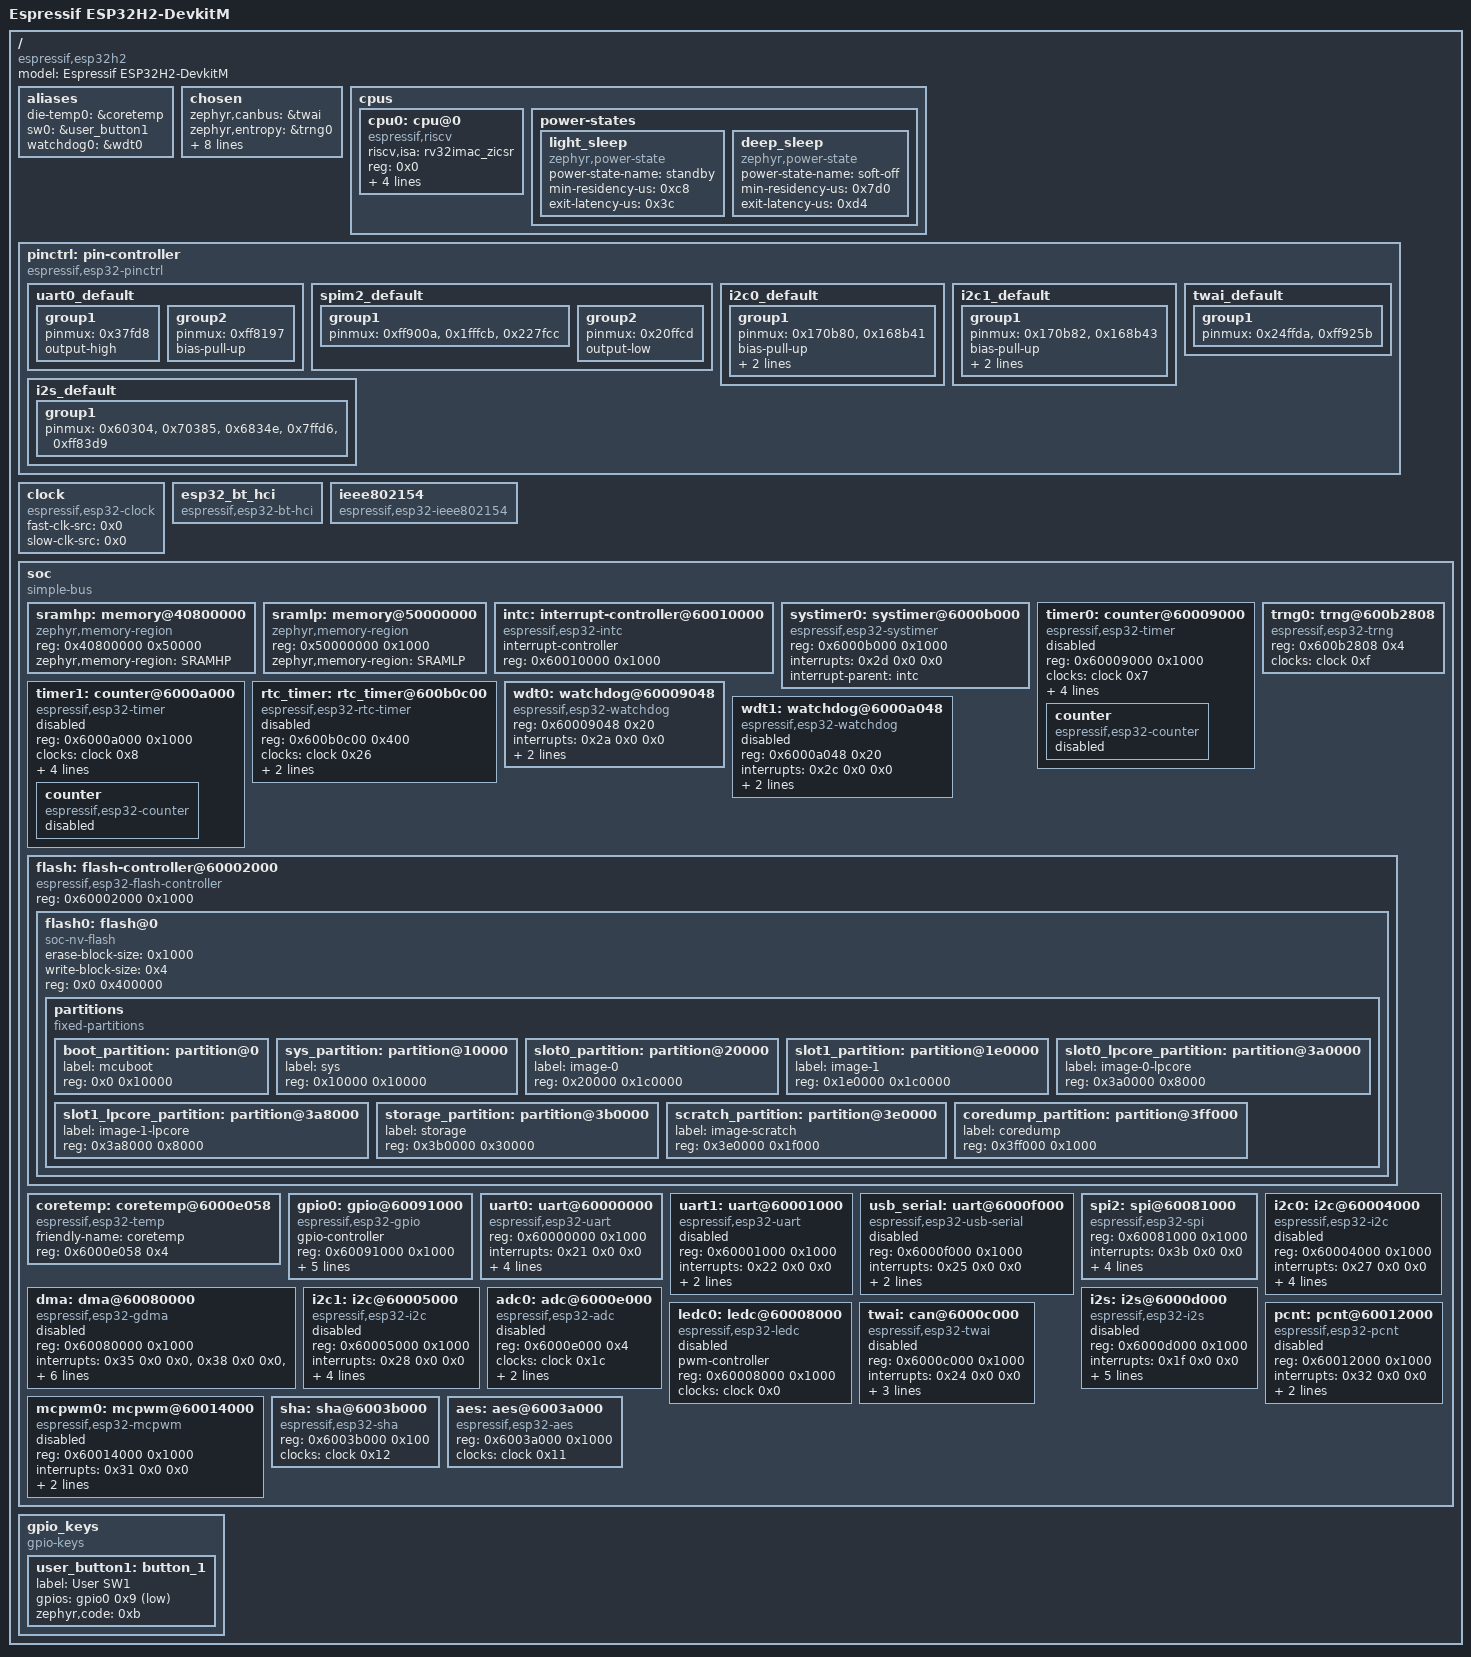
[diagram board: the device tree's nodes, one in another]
/dts-v1/;

/* node '/' defined in zephyr/dts/riscv/espressif/esp32h2/esp32h2_common.dtsi:15 */
/ {
	#address-cells = < 0x1 >;            /* in zephyr/dts/riscv/espressif/esp32h2/esp32h2_common.dtsi:16 */
	#size-cells = < 0x1 >;               /* in zephyr/dts/riscv/espressif/esp32h2/esp32h2_common.dtsi:17 */
	model = "Espressif ESP32H2-DevkitM"; /* in zephyr/boards/espressif/esp32h2_devkitm/esp32h2_devkitm.dts:15 */
	compatible = "espressif,esp32h2";    /* in zephyr/boards/espressif/esp32h2_devkitm/esp32h2_devkitm.dts:16 */

	/* node '/aliases' defined in zephyr/dts/riscv/espressif/esp32h2/esp32h2_common.dtsi:19 */
	aliases {
		die-temp0 = &coretemp; /* in zephyr/dts/riscv/espressif/esp32h2/esp32h2_common.dtsi:20 */
		sw0 = &user_button1;   /* in zephyr/boards/espressif/esp32h2_devkitm/esp32h2_devkitm.dts:28 */
		watchdog0 = &wdt0;     /* in zephyr/boards/espressif/esp32h2_devkitm/esp32h2_devkitm.dts:29 */
	};

	/* node '/chosen' defined in zephyr/dts/riscv/espressif/esp32h2/esp32h2_common.dtsi:23 */
	chosen {
		zephyr,canbus = &twai;                    /* in zephyr/dts/riscv/espressif/esp32h2/esp32h2_common.dtsi:24 */
		zephyr,entropy = &trng0;                  /* in zephyr/dts/riscv/espressif/esp32h2/esp32h2_common.dtsi:25 */
		zephyr,flash-controller = &flash;         /* in zephyr/dts/riscv/espressif/esp32h2/esp32h2_common.dtsi:26 */
		zephyr,bt-hci = &esp32_bt_hci;            /* in zephyr/dts/riscv/espressif/esp32h2/esp32h2_common.dtsi:27 */
		zephyr,sram = &sramhp;                    /* in zephyr/boards/espressif/esp32h2_devkitm/esp32h2_devkitm.dts:19 */
		zephyr,console = &uart0;                  /* in zephyr/boards/espressif/esp32h2_devkitm/esp32h2_devkitm.dts:20 */
		zephyr,shell-uart = &uart0;               /* in zephyr/boards/espressif/esp32h2_devkitm/esp32h2_devkitm.dts:21 */
		zephyr,flash = &flash0;                   /* in zephyr/boards/espressif/esp32h2_devkitm/esp32h2_devkitm.dts:22 */
		zephyr,code-partition = &slot0_partition; /* in zephyr/boards/espressif/esp32h2_devkitm/esp32h2_devkitm.dts:23 */
		zephyr,ieee802154 = &ieee802154;          /* in zephyr/boards/espressif/esp32h2_devkitm/esp32h2_devkitm.dts:24 */
	};

	/* node '/cpus' defined in zephyr/dts/riscv/espressif/esp32h2/esp32h2_common.dtsi:30 */
	cpus {
		#address-cells = < 0x1 >; /* in zephyr/dts/riscv/espressif/esp32h2/esp32h2_common.dtsi:31 */
		#size-cells = < 0x0 >;    /* in zephyr/dts/riscv/espressif/esp32h2/esp32h2_common.dtsi:32 */

		/* node '/cpus/cpu@0' defined in zephyr/dts/riscv/espressif/esp32h2/esp32h2_common.dtsi:34 */
		cpu0: cpu@0 {
			device_type = "cpu";                             /* in zephyr/dts/riscv/espressif/esp32h2/esp32h2_common.dtsi:35 */
			compatible = "espressif,riscv";                  /* in zephyr/dts/riscv/espressif/esp32h2/esp32h2_common.dtsi:36 */
			riscv,isa = "rv32imac_zicsr";                    /* in zephyr/dts/riscv/espressif/esp32h2/esp32h2_common.dtsi:37 */
			reg = < 0x0 >;                                   /* in zephyr/dts/riscv/espressif/esp32h2/esp32h2_common.dtsi:38 */
			cpu-power-states = < &light_sleep &deep_sleep >; /* in zephyr/dts/riscv/espressif/esp32h2/esp32h2_common.dtsi:39 */
			clock-source = < 0x1 >;                          /* in zephyr/dts/riscv/espressif/esp32h2/esp32h2_common.dtsi:40 */
			clock-frequency = < 0x5b8d800 >;                 /* in zephyr/dts/riscv/espressif/esp32h2/esp32h2_common.dtsi:41 */
			xtal-freq = < 0x1e84800 >;                       /* in zephyr/dts/riscv/espressif/esp32h2/esp32h2_common.dtsi:42 */
		};

		/* node '/cpus/power-states' defined in zephyr/dts/riscv/espressif/esp32h2/esp32h2_common.dtsi:45 */
		power-states {

			/* node '/cpus/power-states/light_sleep' defined in zephyr/dts/riscv/espressif/esp32h2/esp32h2_common.dtsi:46 */
			light_sleep: light_sleep {
				compatible = "zephyr,power-state"; /* in zephyr/dts/riscv/espressif/esp32h2/esp32h2_common.dtsi:47 */
				power-state-name = "standby";      /* in zephyr/dts/riscv/espressif/esp32h2/esp32h2_common.dtsi:48 */
				min-residency-us = < 0xc8 >;       /* in zephyr/dts/riscv/espressif/esp32h2/esp32h2_common.dtsi:49 */
				exit-latency-us = < 0x3c >;        /* in zephyr/dts/riscv/espressif/esp32h2/esp32h2_common.dtsi:50 */
				phandle = < 0x1 >;                 /* in zephyr/dts/riscv/espressif/esp32h2/esp32h2_common.dtsi:39 */
			};

			/* node '/cpus/power-states/deep_sleep' defined in zephyr/dts/riscv/espressif/esp32h2/esp32h2_common.dtsi:53 */
			deep_sleep: deep_sleep {
				compatible = "zephyr,power-state"; /* in zephyr/dts/riscv/espressif/esp32h2/esp32h2_common.dtsi:54 */
				power-state-name = "soft-off";     /* in zephyr/dts/riscv/espressif/esp32h2/esp32h2_common.dtsi:55 */
				min-residency-us = < 0x7d0 >;      /* in zephyr/dts/riscv/espressif/esp32h2/esp32h2_common.dtsi:56 */
				exit-latency-us = < 0xd4 >;        /* in zephyr/dts/riscv/espressif/esp32h2/esp32h2_common.dtsi:57 */
				phandle = < 0x2 >;                 /* in zephyr/dts/riscv/espressif/esp32h2/esp32h2_common.dtsi:39 */
			};
		};
	};

	/* node '/pin-controller' defined in zephyr/dts/riscv/espressif/esp32h2/esp32h2_common.dtsi:62 */
	pinctrl: pin-controller {
		compatible = "espressif,esp32-pinctrl"; /* in zephyr/dts/riscv/espressif/esp32h2/esp32h2_common.dtsi:63 */
		status = "okay";                        /* in zephyr/dts/riscv/espressif/esp32h2/esp32h2_common.dtsi:64 */

		/* node '/pin-controller/uart0_default' defined in zephyr/boards/espressif/esp32h2_devkitm/esp32h2_devkitm-pinctrl.dtsi:12 */
		uart0_default: uart0_default {
			phandle = < 0x5 >; /* in zephyr/boards/espressif/esp32h2_devkitm/esp32h2_devkitm.dts:46 */

			/* node '/pin-controller/uart0_default/group1' defined in zephyr/boards/espressif/esp32h2_devkitm/esp32h2_devkitm-pinctrl.dtsi:13 */
			group1 {
				pinmux = < 0x37fd8 >; /* in zephyr/boards/espressif/esp32h2_devkitm/esp32h2_devkitm-pinctrl.dtsi:14 */
				output-high;          /* in zephyr/boards/espressif/esp32h2_devkitm/esp32h2_devkitm-pinctrl.dtsi:15 */
			};

			/* node '/pin-controller/uart0_default/group2' defined in zephyr/boards/espressif/esp32h2_devkitm/esp32h2_devkitm-pinctrl.dtsi:18 */
			group2 {
				pinmux = < 0xff8197 >; /* in zephyr/boards/espressif/esp32h2_devkitm/esp32h2_devkitm-pinctrl.dtsi:19 */
				bias-pull-up;          /* in zephyr/boards/espressif/esp32h2_devkitm/esp32h2_devkitm-pinctrl.dtsi:20 */
			};
		};

		/* node '/pin-controller/spim2_default' defined in zephyr/boards/espressif/esp32h2_devkitm/esp32h2_devkitm-pinctrl.dtsi:24 */
		spim2_default: spim2_default {
			phandle = < 0x6 >; /* in zephyr/boards/espressif/esp32h2_devkitm/esp32h2_devkitm.dts:70 */

			/* node '/pin-controller/spim2_default/group1' defined in zephyr/boards/espressif/esp32h2_devkitm/esp32h2_devkitm-pinctrl.dtsi:25 */
			group1 {
				pinmux = < 0xff900a >,
				         < 0x1fffcb >,
				         < 0x227fcc >; /* in zephyr/boards/espressif/esp32h2_devkitm/esp32h2_devkitm-pinctrl.dtsi:26 */
			};

			/* node '/pin-controller/spim2_default/group2' defined in zephyr/boards/espressif/esp32h2_devkitm/esp32h2_devkitm-pinctrl.dtsi:31 */
			group2 {
				pinmux = < 0x20ffcd >; /* in zephyr/boards/espressif/esp32h2_devkitm/esp32h2_devkitm-pinctrl.dtsi:32 */
				output-low;            /* in zephyr/boards/espressif/esp32h2_devkitm/esp32h2_devkitm-pinctrl.dtsi:33 */
			};
		};

		/* node '/pin-controller/i2c0_default' defined in zephyr/boards/espressif/esp32h2_devkitm/esp32h2_devkitm-pinctrl.dtsi:37 */
		i2c0_default: i2c0_default {
			phandle = < 0x7 >; /* in zephyr/boards/espressif/esp32h2_devkitm/esp32h2_devkitm.dts:76 */

			/* node '/pin-controller/i2c0_default/group1' defined in zephyr/boards/espressif/esp32h2_devkitm/esp32h2_devkitm-pinctrl.dtsi:38 */
			group1 {
				pinmux = < 0x170b80 >,
				         < 0x168b41 >; /* in zephyr/boards/espressif/esp32h2_devkitm/esp32h2_devkitm-pinctrl.dtsi:39 */
				bias-pull-up;          /* in zephyr/boards/espressif/esp32h2_devkitm/esp32h2_devkitm-pinctrl.dtsi:41 */
				drive-open-drain;      /* in zephyr/boards/espressif/esp32h2_devkitm/esp32h2_devkitm-pinctrl.dtsi:42 */
				output-high;           /* in zephyr/boards/espressif/esp32h2_devkitm/esp32h2_devkitm-pinctrl.dtsi:43 */
			};
		};

		/* node '/pin-controller/i2c1_default' defined in zephyr/boards/espressif/esp32h2_devkitm/esp32h2_devkitm-pinctrl.dtsi:47 */
		i2c1_default: i2c1_default {
			phandle = < 0x8 >; /* in zephyr/boards/espressif/esp32h2_devkitm/esp32h2_devkitm.dts:82 */

			/* node '/pin-controller/i2c1_default/group1' defined in zephyr/boards/espressif/esp32h2_devkitm/esp32h2_devkitm-pinctrl.dtsi:48 */
			group1 {
				pinmux = < 0x170b82 >,
				         < 0x168b43 >; /* in zephyr/boards/espressif/esp32h2_devkitm/esp32h2_devkitm-pinctrl.dtsi:49 */
				bias-pull-up;          /* in zephyr/boards/espressif/esp32h2_devkitm/esp32h2_devkitm-pinctrl.dtsi:51 */
				drive-open-drain;      /* in zephyr/boards/espressif/esp32h2_devkitm/esp32h2_devkitm-pinctrl.dtsi:52 */
				output-high;           /* in zephyr/boards/espressif/esp32h2_devkitm/esp32h2_devkitm-pinctrl.dtsi:53 */
			};
		};

		/* node '/pin-controller/i2s_default' defined in zephyr/boards/espressif/esp32h2_devkitm/esp32h2_devkitm-pinctrl.dtsi:57 */
		i2s_default: i2s_default {
			phandle = < 0xa >; /* in zephyr/boards/espressif/esp32h2_devkitm/esp32h2_devkitm.dts:87 */

			/* node '/pin-controller/i2s_default/group1' defined in zephyr/boards/espressif/esp32h2_devkitm/esp32h2_devkitm-pinctrl.dtsi:58 */
			group1 {
				pinmux = < 0x60304 >,
				         < 0x70385 >,
				         < 0x6834e >,
				         < 0x7ffd6 >,
				         < 0xff83d9 >; /* in zephyr/boards/espressif/esp32h2_devkitm/esp32h2_devkitm-pinctrl.dtsi:59 */
			};
		};

		/* node '/pin-controller/twai_default' defined in zephyr/boards/espressif/esp32h2_devkitm/esp32h2_devkitm-pinctrl.dtsi:67 */
		twai_default: twai_default {
			phandle = < 0xb >; /* in zephyr/boards/espressif/esp32h2_devkitm/esp32h2_devkitm.dts:92 */

			/* node '/pin-controller/twai_default/group1' defined in zephyr/boards/espressif/esp32h2_devkitm/esp32h2_devkitm-pinctrl.dtsi:68 */
			group1 {
				pinmux = < 0x24ffda >,
				         < 0xff925b >; /* in zephyr/boards/espressif/esp32h2_devkitm/esp32h2_devkitm-pinctrl.dtsi:69 */
			};
		};
	};

	/* node '/clock' defined in zephyr/dts/riscv/espressif/esp32h2/esp32h2_common.dtsi:67 */
	clock: clock {
		compatible = "espressif,esp32-clock"; /* in zephyr/dts/riscv/espressif/esp32h2/esp32h2_common.dtsi:68 */
		fast-clk-src = < 0x0 >;               /* in zephyr/dts/riscv/espressif/esp32h2/esp32h2_common.dtsi:69 */
		slow-clk-src = < 0x0 >;               /* in zephyr/dts/riscv/espressif/esp32h2/esp32h2_common.dtsi:70 */
		#clock-cells = < 0x1 >;               /* in zephyr/dts/riscv/espressif/esp32h2/esp32h2_common.dtsi:71 */
		status = "okay";                      /* in zephyr/dts/riscv/espressif/esp32h2/esp32h2_common.dtsi:72 */
		phandle = < 0x4 >;                    /* in zephyr/dts/riscv/espressif/esp32h2/esp32h2_common.dtsi:125 */
	};

	/* node '/esp32_bt_hci' defined in zephyr/dts/riscv/espressif/esp32h2/esp32h2_common.dtsi:75 */
	esp32_bt_hci: esp32_bt_hci {
		compatible = "espressif,esp32-bt-hci"; /* in zephyr/dts/riscv/espressif/esp32h2/esp32h2_common.dtsi:76 */
		status = "okay";                       /* in zephyr/boards/espressif/esp32h2_devkitm/esp32h2_devkitm.dts:101 */
	};

	/* node '/ieee802154' defined in zephyr/dts/riscv/espressif/esp32h2/esp32h2_common.dtsi:80 */
	ieee802154: ieee802154 {
		compatible = "espressif,esp32-ieee802154"; /* in zephyr/dts/riscv/espressif/esp32h2/esp32h2_common.dtsi:81 */
		status = "okay";                           /* in zephyr/boards/espressif/esp32h2_devkitm/esp32h2_devkitm.dts:97 */
	};

	/* node '/soc' defined in zephyr/dts/riscv/espressif/esp32h2/esp32h2_common.dtsi:85 */
	soc {
		#address-cells = < 0x1 >;  /* in zephyr/dts/riscv/espressif/esp32h2/esp32h2_common.dtsi:86 */
		#size-cells = < 0x1 >;     /* in zephyr/dts/riscv/espressif/esp32h2/esp32h2_common.dtsi:87 */
		compatible = "simple-bus"; /* in zephyr/dts/riscv/espressif/esp32h2/esp32h2_common.dtsi:88 */
		ranges;                    /* in zephyr/dts/riscv/espressif/esp32h2/esp32h2_common.dtsi:89 */

		/* node '/soc/memory@40800000' defined in zephyr/dts/riscv/espressif/esp32h2/esp32h2_common.dtsi:91 */
		sramhp: memory@40800000 {
			compatible = "zephyr,memory-region",
			             "mmio-sram";            /* in zephyr/dts/riscv/espressif/esp32h2/esp32h2_common.dtsi:92 */
			reg = < 0x40800000 0x50000 >;        /* in zephyr/dts/riscv/espressif/esp32h2/esp32h2_common.dtsi:93 */
			zephyr,memory-region = "SRAMHP";     /* in zephyr/dts/riscv/espressif/esp32h2/esp32h2_common.dtsi:94 */
		};

		/* node '/soc/memory@50000000' defined in zephyr/dts/riscv/espressif/esp32h2/esp32h2_common.dtsi:97 */
		sramlp: memory@50000000 {
			#address-cells = < 0x1 >;            /* in zephyr/dts/riscv/espressif/esp32h2/esp32h2_common.dtsi:98 */
			#size-cells = < 0x1 >;               /* in zephyr/dts/riscv/espressif/esp32h2/esp32h2_common.dtsi:99 */
			compatible = "zephyr,memory-region",
			             "mmio-sram";            /* in zephyr/dts/riscv/espressif/esp32h2/esp32h2_common.dtsi:100 */
			reg = < 0x50000000 0x1000 >;         /* in zephyr/dts/riscv/espressif/esp32h2/esp32h2_common.dtsi:101 */
			zephyr,memory-region = "SRAMLP";     /* in zephyr/dts/riscv/espressif/esp32h2/esp32h2_common.dtsi:102 */
		};

		/* node '/soc/interrupt-controller@60010000' defined in zephyr/dts/riscv/espressif/esp32h2/esp32h2_common.dtsi:105 */
		intc: interrupt-controller@60010000 {
			compatible = "espressif,esp32-intc"; /* in zephyr/dts/riscv/espressif/esp32h2/esp32h2_common.dtsi:106 */
			#address-cells = < 0x0 >;            /* in zephyr/dts/riscv/espressif/esp32h2/esp32h2_common.dtsi:107 */
			#interrupt-cells = < 0x3 >;          /* in zephyr/dts/riscv/espressif/esp32h2/esp32h2_common.dtsi:108 */
			interrupt-controller;                /* in zephyr/dts/riscv/espressif/esp32h2/esp32h2_common.dtsi:109 */
			reg = < 0x60010000 0x1000 >;         /* in zephyr/dts/riscv/espressif/esp32h2/esp32h2_common.dtsi:110 */
			status = "okay";                     /* in zephyr/dts/riscv/espressif/esp32h2/esp32h2_common.dtsi:111 */
			phandle = < 0x3 >;                   /* in zephyr/dts/riscv/espressif/esp32h2/esp32h2_common.dtsi:118 */
		};

		/* node '/soc/systimer@6000b000' defined in zephyr/dts/riscv/espressif/esp32h2/esp32h2_common.dtsi:114 */
		systimer0: systimer@6000b000 {
			compatible = "espressif,esp32-systimer"; /* in zephyr/dts/riscv/espressif/esp32h2/esp32h2_common.dtsi:115 */
			reg = < 0x6000b000 0x1000 >;             /* in zephyr/dts/riscv/espressif/esp32h2/esp32h2_common.dtsi:116 */
			interrupts = < 0x2d 0x0 0x0 >;           /* in zephyr/dts/riscv/espressif/esp32h2/esp32h2_common.dtsi:117 */
			interrupt-parent = < &intc >;            /* in zephyr/dts/riscv/espressif/esp32h2/esp32h2_common.dtsi:118 */
			status = "okay";                         /* in zephyr/dts/riscv/espressif/esp32h2/esp32h2_common.dtsi:119 */
		};

		/* node '/soc/counter@60009000' defined in zephyr/dts/riscv/espressif/esp32h2/esp32h2_common.dtsi:122 */
		timer0: counter@60009000 {
			compatible = "espressif,esp32-timer"; /* in zephyr/dts/riscv/espressif/esp32h2/esp32h2_common.dtsi:123 */
			reg = < 0x60009000 0x1000 >;          /* in zephyr/dts/riscv/espressif/esp32h2/esp32h2_common.dtsi:124 */
			clocks = < &clock 0x7 >;              /* in zephyr/dts/riscv/espressif/esp32h2/esp32h2_common.dtsi:125 */
			group = < 0x0 >;                      /* in zephyr/dts/riscv/espressif/esp32h2/esp32h2_common.dtsi:126 */
			index = < 0x0 >;                      /* in zephyr/dts/riscv/espressif/esp32h2/esp32h2_common.dtsi:127 */
			interrupts = < 0x29 0x0 0x0 >;        /* in zephyr/dts/riscv/espressif/esp32h2/esp32h2_common.dtsi:128 */
			interrupt-parent = < &intc >;         /* in zephyr/dts/riscv/espressif/esp32h2/esp32h2_common.dtsi:129 */
			status = "disabled";                  /* in zephyr/dts/riscv/espressif/esp32h2/esp32h2_common.dtsi:130 */

			/* node '/soc/counter@60009000/counter' defined in zephyr/dts/riscv/espressif/esp32h2/esp32h2_common.dtsi:132 */
			counter {
				compatible = "espressif,esp32-counter"; /* in zephyr/dts/riscv/espressif/esp32h2/esp32h2_common.dtsi:133 */
				status = "disabled";                    /* in zephyr/dts/riscv/espressif/esp32h2/esp32h2_common.dtsi:134 */
			};
		};

		/* node '/soc/counter@6000a000' defined in zephyr/dts/riscv/espressif/esp32h2/esp32h2_common.dtsi:138 */
		timer1: counter@6000a000 {
			compatible = "espressif,esp32-timer"; /* in zephyr/dts/riscv/espressif/esp32h2/esp32h2_common.dtsi:139 */
			reg = < 0x6000a000 0x1000 >;          /* in zephyr/dts/riscv/espressif/esp32h2/esp32h2_common.dtsi:140 */
			clocks = < &clock 0x8 >;              /* in zephyr/dts/riscv/espressif/esp32h2/esp32h2_common.dtsi:141 */
			group = < 0x1 >;                      /* in zephyr/dts/riscv/espressif/esp32h2/esp32h2_common.dtsi:142 */
			index = < 0x0 >;                      /* in zephyr/dts/riscv/espressif/esp32h2/esp32h2_common.dtsi:143 */
			interrupts = < 0x2b 0x0 0x0 >;        /* in zephyr/dts/riscv/espressif/esp32h2/esp32h2_common.dtsi:144 */
			interrupt-parent = < &intc >;         /* in zephyr/dts/riscv/espressif/esp32h2/esp32h2_common.dtsi:145 */
			status = "disabled";                  /* in zephyr/dts/riscv/espressif/esp32h2/esp32h2_common.dtsi:146 */

			/* node '/soc/counter@6000a000/counter' defined in zephyr/dts/riscv/espressif/esp32h2/esp32h2_common.dtsi:148 */
			counter {
				compatible = "espressif,esp32-counter"; /* in zephyr/dts/riscv/espressif/esp32h2/esp32h2_common.dtsi:149 */
				status = "disabled";                    /* in zephyr/dts/riscv/espressif/esp32h2/esp32h2_common.dtsi:150 */
			};
		};

		/* node '/soc/rtc_timer@600b0c00' defined in zephyr/dts/riscv/espressif/esp32h2/esp32h2_common.dtsi:154 */
		rtc_timer: rtc_timer@600b0c00 {
			compatible = "espressif,esp32-rtc-timer"; /* in zephyr/dts/riscv/espressif/esp32h2/esp32h2_common.dtsi:155 */
			reg = < 0x600b0c00 0x400 >;               /* in zephyr/dts/riscv/espressif/esp32h2/esp32h2_common.dtsi:156 */
			clocks = < &clock 0x26 >;                 /* in zephyr/dts/riscv/espressif/esp32h2/esp32h2_common.dtsi:157 */
			interrupts = < 0x2 0x0 0x0 >;             /* in zephyr/dts/riscv/espressif/esp32h2/esp32h2_common.dtsi:158 */
			interrupt-parent = < &intc >;             /* in zephyr/dts/riscv/espressif/esp32h2/esp32h2_common.dtsi:159 */
			status = "disabled";                      /* in zephyr/dts/riscv/espressif/esp32h2/esp32h2_common.dtsi:160 */
		};

		/* node '/soc/trng@600b2808' defined in zephyr/dts/riscv/espressif/esp32h2/esp32h2_common.dtsi:163 */
		trng0: trng@600b2808 {
			compatible = "espressif,esp32-trng"; /* in zephyr/dts/riscv/espressif/esp32h2/esp32h2_common.dtsi:164 */
			reg = < 0x600b2808 0x4 >;            /* in zephyr/dts/riscv/espressif/esp32h2/esp32h2_common.dtsi:165 */
			clocks = < &clock 0xf >;             /* in zephyr/dts/riscv/espressif/esp32h2/esp32h2_common.dtsi:166 */
			status = "okay";                     /* in zephyr/boards/espressif/esp32h2_devkitm/esp32h2_devkitm.dts:59 */
		};

		/* node '/soc/watchdog@60009048' defined in zephyr/dts/riscv/espressif/esp32h2/esp32h2_common.dtsi:170 */
		wdt0: watchdog@60009048 {
			compatible = "espressif,esp32-watchdog"; /* in zephyr/dts/riscv/espressif/esp32h2/esp32h2_common.dtsi:171 */
			reg = < 0x60009048 0x20 >;               /* in zephyr/dts/riscv/espressif/esp32h2/esp32h2_common.dtsi:172 */
			interrupts = < 0x2a 0x0 0x0 >;           /* in zephyr/dts/riscv/espressif/esp32h2/esp32h2_common.dtsi:173 */
			interrupt-parent = < &intc >;            /* in zephyr/dts/riscv/espressif/esp32h2/esp32h2_common.dtsi:174 */
			clocks = < &clock 0x7 >;                 /* in zephyr/dts/riscv/espressif/esp32h2/esp32h2_common.dtsi:175 */
			status = "okay";                         /* in zephyr/boards/espressif/esp32h2_devkitm/esp32h2_devkitm.dts:55 */
		};

		/* node '/soc/watchdog@6000a048' defined in zephyr/dts/riscv/espressif/esp32h2/esp32h2_common.dtsi:179 */
		wdt1: watchdog@6000a048 {
			compatible = "espressif,esp32-watchdog"; /* in zephyr/dts/riscv/espressif/esp32h2/esp32h2_common.dtsi:180 */
			reg = < 0x6000a048 0x20 >;               /* in zephyr/dts/riscv/espressif/esp32h2/esp32h2_common.dtsi:181 */
			interrupts = < 0x2c 0x0 0x0 >;           /* in zephyr/dts/riscv/espressif/esp32h2/esp32h2_common.dtsi:182 */
			interrupt-parent = < &intc >;            /* in zephyr/dts/riscv/espressif/esp32h2/esp32h2_common.dtsi:183 */
			clocks = < &clock 0x8 >;                 /* in zephyr/dts/riscv/espressif/esp32h2/esp32h2_common.dtsi:184 */
			status = "disabled";                     /* in zephyr/dts/riscv/espressif/esp32h2/esp32h2_common.dtsi:185 */
		};

		/* node '/soc/flash-controller@60002000' defined in zephyr/dts/riscv/espressif/esp32h2/esp32h2_common.dtsi:188 */
		flash: flash-controller@60002000 {
			compatible = "espressif,esp32-flash-controller"; /* in zephyr/dts/riscv/espressif/esp32h2/esp32h2_common.dtsi:189 */
			reg = < 0x60002000 0x1000 >;                     /* in zephyr/dts/riscv/espressif/esp32h2/esp32h2_common.dtsi:190 */
			#address-cells = < 0x1 >;                        /* in zephyr/dts/riscv/espressif/esp32h2/esp32h2_common.dtsi:192 */
			#size-cells = < 0x1 >;                           /* in zephyr/dts/riscv/espressif/esp32h2/esp32h2_common.dtsi:193 */

			/* node '/soc/flash-controller@60002000/flash@0' defined in zephyr/dts/riscv/espressif/esp32h2/esp32h2_common.dtsi:195 */
			flash0: flash@0 {
				compatible = "soc-nv-flash";   /* in zephyr/dts/riscv/espressif/esp32h2/esp32h2_common.dtsi:196 */
				erase-block-size = < 0x1000 >; /* in zephyr/dts/riscv/espressif/esp32h2/esp32h2_common.dtsi:197 */
				write-block-size = < 0x4 >;    /* in zephyr/dts/riscv/espressif/esp32h2/esp32h2_common.dtsi:198 */
				reg = < 0x0 0x400000 >;        /* in zephyr/dts/riscv/espressif/esp32h2/esp32h2_mini_h4.dtsi:11 */

				/* node '/soc/flash-controller@60002000/flash@0/partitions' defined in zephyr/dts/vendor/espressif/partitions_0x0_default_4M.dtsi:8 */
				partitions {
					compatible = "fixed-partitions"; /* in zephyr/dts/vendor/espressif/partitions_0x0_default_4M.dtsi:9 */
					#address-cells = < 0x1 >;        /* in zephyr/dts/vendor/espressif/partitions_0x0_default_4M.dtsi:10 */
					#size-cells = < 0x1 >;           /* in zephyr/dts/vendor/espressif/partitions_0x0_default_4M.dtsi:11 */

					/* node '/soc/flash-controller@60002000/flash@0/partitions/partition@0' defined in zephyr/dts/vendor/espressif/partitions_0x0_default_4M.dtsi:13 */
					boot_partition: partition@0 {
						label = "mcuboot";     /* in zephyr/dts/vendor/espressif/partitions_0x0_default_4M.dtsi:14 */
						reg = < 0x0 0x10000 >; /* in zephyr/dts/vendor/espressif/partitions_0x0_default_4M.dtsi:15 */
					};

					/* node '/soc/flash-controller@60002000/flash@0/partitions/partition@10000' defined in zephyr/dts/vendor/espressif/partitions_0x0_default_4M.dtsi:18 */
					sys_partition: partition@10000 {
						label = "sys";             /* in zephyr/dts/vendor/espressif/partitions_0x0_default_4M.dtsi:19 */
						reg = < 0x10000 0x10000 >; /* in zephyr/dts/vendor/espressif/partitions_0x0_default_4M.dtsi:20 */
					};

					/* node '/soc/flash-controller@60002000/flash@0/partitions/partition@20000' defined in zephyr/dts/vendor/espressif/partitions_0x0_default_4M.dtsi:23 */
					slot0_partition: partition@20000 {
						label = "image-0";          /* in zephyr/dts/vendor/espressif/partitions_0x0_default_4M.dtsi:24 */
						reg = < 0x20000 0x1c0000 >; /* in zephyr/dts/vendor/espressif/partitions_0x0_default_4M.dtsi:25 */
					};

					/* node '/soc/flash-controller@60002000/flash@0/partitions/partition@1e0000' defined in zephyr/dts/vendor/espressif/partitions_0x0_default_4M.dtsi:28 */
					slot1_partition: partition@1e0000 {
						label = "image-1";           /* in zephyr/dts/vendor/espressif/partitions_0x0_default_4M.dtsi:29 */
						reg = < 0x1e0000 0x1c0000 >; /* in zephyr/dts/vendor/espressif/partitions_0x0_default_4M.dtsi:30 */
					};

					/* node '/soc/flash-controller@60002000/flash@0/partitions/partition@3a0000' defined in zephyr/dts/vendor/espressif/partitions_0x0_default_4M.dtsi:33 */
					slot0_lpcore_partition: partition@3a0000 {
						label = "image-0-lpcore";  /* in zephyr/dts/vendor/espressif/partitions_0x0_default_4M.dtsi:34 */
						reg = < 0x3a0000 0x8000 >; /* in zephyr/dts/vendor/espressif/partitions_0x0_default_4M.dtsi:35 */
					};

					/* node '/soc/flash-controller@60002000/flash@0/partitions/partition@3a8000' defined in zephyr/dts/vendor/espressif/partitions_0x0_default_4M.dtsi:38 */
					slot1_lpcore_partition: partition@3a8000 {
						label = "image-1-lpcore";  /* in zephyr/dts/vendor/espressif/partitions_0x0_default_4M.dtsi:39 */
						reg = < 0x3a8000 0x8000 >; /* in zephyr/dts/vendor/espressif/partitions_0x0_default_4M.dtsi:40 */
					};

					/* node '/soc/flash-controller@60002000/flash@0/partitions/partition@3b0000' defined in zephyr/dts/vendor/espressif/partitions_0x0_default_4M.dtsi:43 */
					storage_partition: partition@3b0000 {
						label = "storage";          /* in zephyr/dts/vendor/espressif/partitions_0x0_default_4M.dtsi:44 */
						reg = < 0x3b0000 0x30000 >; /* in zephyr/dts/vendor/espressif/partitions_0x0_default_4M.dtsi:45 */
					};

					/* node '/soc/flash-controller@60002000/flash@0/partitions/partition@3e0000' defined in zephyr/dts/vendor/espressif/partitions_0x0_default_4M.dtsi:48 */
					scratch_partition: partition@3e0000 {
						label = "image-scratch";    /* in zephyr/dts/vendor/espressif/partitions_0x0_default_4M.dtsi:49 */
						reg = < 0x3e0000 0x1f000 >; /* in zephyr/dts/vendor/espressif/partitions_0x0_default_4M.dtsi:50 */
					};

					/* node '/soc/flash-controller@60002000/flash@0/partitions/partition@3ff000' defined in zephyr/dts/vendor/espressif/partitions_0x0_default_4M.dtsi:53 */
					coredump_partition: partition@3ff000 {
						label = "coredump";        /* in zephyr/dts/vendor/espressif/partitions_0x0_default_4M.dtsi:54 */
						reg = < 0x3ff000 0x1000 >; /* in zephyr/dts/vendor/espressif/partitions_0x0_default_4M.dtsi:55 */
					};
				};
			};
		};

		/* node '/soc/coretemp@6000e058' defined in zephyr/dts/riscv/espressif/esp32h2/esp32h2_common.dtsi:203 */
		coretemp: coretemp@6000e058 {
			compatible = "espressif,esp32-temp"; /* in zephyr/dts/riscv/espressif/esp32h2/esp32h2_common.dtsi:204 */
			friendly-name = "coretemp";          /* in zephyr/dts/riscv/espressif/esp32h2/esp32h2_common.dtsi:205 */
			reg = < 0x6000e058 0x4 >;            /* in zephyr/dts/riscv/espressif/esp32h2/esp32h2_common.dtsi:206 */
			status = "okay";                     /* in zephyr/boards/espressif/esp32h2_devkitm/esp32h2_devkitm.dts:63 */
		};

		/* node '/soc/gpio@60091000' defined in zephyr/dts/riscv/espressif/esp32h2/esp32h2_common.dtsi:210 */
		gpio0: gpio@60091000 {
			compatible = "espressif,esp32-gpio"; /* in zephyr/dts/riscv/espressif/esp32h2/esp32h2_common.dtsi:211 */
			gpio-controller;                     /* in zephyr/dts/riscv/espressif/esp32h2/esp32h2_common.dtsi:212 */
			#gpio-cells = < 0x2 >;               /* in zephyr/dts/riscv/espressif/esp32h2/esp32h2_common.dtsi:213 */
			reg = < 0x60091000 0x1000 >;         /* in zephyr/dts/riscv/espressif/esp32h2/esp32h2_common.dtsi:214 */
			interrupts = < 0x16 0x0 0x0 >;       /* in zephyr/dts/riscv/espressif/esp32h2/esp32h2_common.dtsi:215 */
			interrupt-parent = < &intc >;        /* in zephyr/dts/riscv/espressif/esp32h2/esp32h2_common.dtsi:216 */
			ngpios = < 0x20 >;                   /* in zephyr/dts/riscv/espressif/esp32h2/esp32h2_common.dtsi:217 */
			gpio-reserved-ranges = < 0x6 0x2 >,
			                       < 0xf 0x7 >,
			                       < 0x1c 0x4 >; /* in zephyr/dts/riscv/espressif/esp32h2/esp32h2_common.dtsi:218 */
			status = "okay";                     /* in zephyr/boards/espressif/esp32h2_devkitm/esp32h2_devkitm.dts:51 */
			phandle = < 0xc >;                   /* in zephyr/boards/espressif/esp32h2_devkitm/esp32h2_devkitm.dts:37 */
		};

		/* node '/soc/uart@60000000' defined in zephyr/dts/riscv/espressif/esp32h2/esp32h2_common.dtsi:223 */
		uart0: uart@60000000 {
			compatible = "espressif,esp32-uart"; /* in zephyr/dts/riscv/espressif/esp32h2/esp32h2_common.dtsi:224 */
			reg = < 0x60000000 0x1000 >;         /* in zephyr/dts/riscv/espressif/esp32h2/esp32h2_common.dtsi:225 */
			interrupts = < 0x21 0x0 0x0 >;       /* in zephyr/dts/riscv/espressif/esp32h2/esp32h2_common.dtsi:227 */
			interrupt-parent = < &intc >;        /* in zephyr/dts/riscv/espressif/esp32h2/esp32h2_common.dtsi:228 */
			clocks = < &clock 0x1 >;             /* in zephyr/dts/riscv/espressif/esp32h2/esp32h2_common.dtsi:229 */
			status = "okay";                     /* in zephyr/boards/espressif/esp32h2_devkitm/esp32h2_devkitm.dts:44 */
			current-speed = < 0x1c200 >;         /* in zephyr/boards/espressif/esp32h2_devkitm/esp32h2_devkitm.dts:45 */
			pinctrl-0 = < &uart0_default >;      /* in zephyr/boards/espressif/esp32h2_devkitm/esp32h2_devkitm.dts:46 */
			pinctrl-names = "default";           /* in zephyr/boards/espressif/esp32h2_devkitm/esp32h2_devkitm.dts:47 */
		};

		/* node '/soc/uart@60001000' defined in zephyr/dts/riscv/espressif/esp32h2/esp32h2_common.dtsi:232 */
		uart1: uart@60001000 {
			compatible = "espressif,esp32-uart"; /* in zephyr/dts/riscv/espressif/esp32h2/esp32h2_common.dtsi:233 */
			reg = < 0x60001000 0x1000 >;         /* in zephyr/dts/riscv/espressif/esp32h2/esp32h2_common.dtsi:234 */
			status = "disabled";                 /* in zephyr/dts/riscv/espressif/esp32h2/esp32h2_common.dtsi:235 */
			interrupts = < 0x22 0x0 0x0 >;       /* in zephyr/dts/riscv/espressif/esp32h2/esp32h2_common.dtsi:236 */
			interrupt-parent = < &intc >;        /* in zephyr/dts/riscv/espressif/esp32h2/esp32h2_common.dtsi:237 */
			clocks = < &clock 0x2 >;             /* in zephyr/dts/riscv/espressif/esp32h2/esp32h2_common.dtsi:238 */
		};

		/* node '/soc/uart@6000f000' defined in zephyr/dts/riscv/espressif/esp32h2/esp32h2_common.dtsi:241 */
		usb_serial: uart@6000f000 {
			compatible = "espressif,esp32-usb-serial"; /* in zephyr/dts/riscv/espressif/esp32h2/esp32h2_common.dtsi:242 */
			reg = < 0x6000f000 0x1000 >;               /* in zephyr/dts/riscv/espressif/esp32h2/esp32h2_common.dtsi:243 */
			status = "disabled";                       /* in zephyr/dts/riscv/espressif/esp32h2/esp32h2_common.dtsi:244 */
			interrupts = < 0x25 0x0 0x0 >;             /* in zephyr/dts/riscv/espressif/esp32h2/esp32h2_common.dtsi:245 */
			interrupt-parent = < &intc >;              /* in zephyr/dts/riscv/espressif/esp32h2/esp32h2_common.dtsi:246 */
			clocks = < &clock 0x3 >;                   /* in zephyr/dts/riscv/espressif/esp32h2/esp32h2_common.dtsi:247 */
		};

		/* node '/soc/spi@60081000' defined in zephyr/dts/riscv/espressif/esp32h2/esp32h2_common.dtsi:250 */
		spi2: spi@60081000 {
			compatible = "espressif,esp32-spi"; /* in zephyr/dts/riscv/espressif/esp32h2/esp32h2_common.dtsi:251 */
			reg = < 0x60081000 0x1000 >;        /* in zephyr/dts/riscv/espressif/esp32h2/esp32h2_common.dtsi:252 */
			interrupts = < 0x3b 0x0 0x0 >;      /* in zephyr/dts/riscv/espressif/esp32h2/esp32h2_common.dtsi:253 */
			interrupt-parent = < &intc >;       /* in zephyr/dts/riscv/espressif/esp32h2/esp32h2_common.dtsi:254 */
			clocks = < &clock 0xd >;            /* in zephyr/dts/riscv/espressif/esp32h2/esp32h2_common.dtsi:255 */
			dma-host = < 0x0 >;                 /* in zephyr/dts/riscv/espressif/esp32h2/esp32h2_common.dtsi:256 */
			#address-cells = < 0x1 >;           /* in zephyr/boards/espressif/esp32h2_devkitm/esp32h2_devkitm.dts:67 */
			#size-cells = < 0x0 >;              /* in zephyr/boards/espressif/esp32h2_devkitm/esp32h2_devkitm.dts:68 */
			status = "okay";                    /* in zephyr/boards/espressif/esp32h2_devkitm/esp32h2_devkitm.dts:69 */
			pinctrl-0 = < &spim2_default >;     /* in zephyr/boards/espressif/esp32h2_devkitm/esp32h2_devkitm.dts:70 */
			pinctrl-names = "default";          /* in zephyr/boards/espressif/esp32h2_devkitm/esp32h2_devkitm.dts:71 */
		};

		/* node '/soc/dma@60080000' defined in zephyr/dts/riscv/espressif/esp32h2/esp32h2_common.dtsi:260 */
		dma: dma@60080000 {
			compatible = "espressif,esp32-gdma"; /* in zephyr/dts/riscv/espressif/esp32h2/esp32h2_common.dtsi:261 */
			reg = < 0x60080000 0x1000 >;         /* in zephyr/dts/riscv/espressif/esp32h2/esp32h2_common.dtsi:262 */
			#dma-cells = < 0x1 >;                /* in zephyr/dts/riscv/espressif/esp32h2/esp32h2_common.dtsi:263 */
			interrupts = < 0x35 0x0 0x0 >,
			             < 0x38 0x0 0x0 >,
			             < 0x36 0x0 0x0 >,
			             < 0x39 0x0 0x0 >,
			             < 0x37 0x0 0x0 >,
			             < 0x3a 0x0 0x0 >;       /* in zephyr/dts/riscv/espressif/esp32h2/esp32h2_common.dtsi:264 */
			interrupt-parent = < &intc >;        /* in zephyr/dts/riscv/espressif/esp32h2/esp32h2_common.dtsi:270 */
			clocks = < &clock 0x17 >;            /* in zephyr/dts/riscv/espressif/esp32h2/esp32h2_common.dtsi:271 */
			dma-channels = < 0x6 >;              /* in zephyr/dts/riscv/espressif/esp32h2/esp32h2_common.dtsi:272 */
			dma-buf-addr-alignment = < 0x4 >;    /* in zephyr/dts/riscv/espressif/esp32h2/esp32h2_common.dtsi:273 */
			status = "disabled";                 /* in zephyr/dts/riscv/espressif/esp32h2/esp32h2_common.dtsi:274 */
			phandle = < 0x9 >;                   /* in zephyr/dts/riscv/espressif/esp32h2/esp32h2_common.dtsi:307 */
		};

		/* node '/soc/i2c@60004000' defined in zephyr/dts/riscv/espressif/esp32h2/esp32h2_common.dtsi:277 */
		i2c0: i2c@60004000 {
			compatible = "espressif,esp32-i2c"; /* in zephyr/dts/riscv/espressif/esp32h2/esp32h2_common.dtsi:278 */
			#address-cells = < 0x1 >;           /* in zephyr/dts/riscv/espressif/esp32h2/esp32h2_common.dtsi:279 */
			#size-cells = < 0x0 >;              /* in zephyr/dts/riscv/espressif/esp32h2/esp32h2_common.dtsi:280 */
			reg = < 0x60004000 0x1000 >;        /* in zephyr/dts/riscv/espressif/esp32h2/esp32h2_common.dtsi:281 */
			interrupts = < 0x27 0x0 0x0 >;      /* in zephyr/dts/riscv/espressif/esp32h2/esp32h2_common.dtsi:282 */
			interrupt-parent = < &intc >;       /* in zephyr/dts/riscv/espressif/esp32h2/esp32h2_common.dtsi:283 */
			clocks = < &clock 0x4 >;            /* in zephyr/dts/riscv/espressif/esp32h2/esp32h2_common.dtsi:284 */
			status = "disabled";                /* in zephyr/dts/riscv/espressif/esp32h2/esp32h2_common.dtsi:285 */
			clock-frequency = < 0x61a80 >;      /* in zephyr/boards/espressif/esp32h2_devkitm/esp32h2_devkitm.dts:75 */
			pinctrl-0 = < &i2c0_default >;      /* in zephyr/boards/espressif/esp32h2_devkitm/esp32h2_devkitm.dts:76 */
			pinctrl-names = "default";          /* in zephyr/boards/espressif/esp32h2_devkitm/esp32h2_devkitm.dts:77 */
		};

		/* node '/soc/i2c@60005000' defined in zephyr/dts/riscv/espressif/esp32h2/esp32h2_common.dtsi:288 */
		i2c1: i2c@60005000 {
			compatible = "espressif,esp32-i2c"; /* in zephyr/dts/riscv/espressif/esp32h2/esp32h2_common.dtsi:289 */
			#address-cells = < 0x1 >;           /* in zephyr/dts/riscv/espressif/esp32h2/esp32h2_common.dtsi:290 */
			#size-cells = < 0x0 >;              /* in zephyr/dts/riscv/espressif/esp32h2/esp32h2_common.dtsi:291 */
			reg = < 0x60005000 0x1000 >;        /* in zephyr/dts/riscv/espressif/esp32h2/esp32h2_common.dtsi:292 */
			interrupts = < 0x28 0x0 0x0 >;      /* in zephyr/dts/riscv/espressif/esp32h2/esp32h2_common.dtsi:293 */
			interrupt-parent = < &intc >;       /* in zephyr/dts/riscv/espressif/esp32h2/esp32h2_common.dtsi:294 */
			clocks = < &clock 0x5 >;            /* in zephyr/dts/riscv/espressif/esp32h2/esp32h2_common.dtsi:295 */
			status = "disabled";                /* in zephyr/dts/riscv/espressif/esp32h2/esp32h2_common.dtsi:296 */
			clock-frequency = < 0x61a80 >;      /* in zephyr/boards/espressif/esp32h2_devkitm/esp32h2_devkitm.dts:81 */
			pinctrl-0 = < &i2c1_default >;      /* in zephyr/boards/espressif/esp32h2_devkitm/esp32h2_devkitm.dts:82 */
			pinctrl-names = "default";          /* in zephyr/boards/espressif/esp32h2_devkitm/esp32h2_devkitm.dts:83 */
		};

		/* node '/soc/i2s@6000d000' defined in zephyr/dts/riscv/espressif/esp32h2/esp32h2_common.dtsi:299 */
		i2s: i2s@6000d000 {
			compatible = "espressif,esp32-i2s"; /* in zephyr/dts/riscv/espressif/esp32h2/esp32h2_common.dtsi:300 */
			#address-cells = < 0x1 >;           /* in zephyr/dts/riscv/espressif/esp32h2/esp32h2_common.dtsi:301 */
			#size-cells = < 0x0 >;              /* in zephyr/dts/riscv/espressif/esp32h2/esp32h2_common.dtsi:302 */
			reg = < 0x6000d000 0x1000 >;        /* in zephyr/dts/riscv/espressif/esp32h2/esp32h2_common.dtsi:303 */
			interrupts = < 0x1f 0x0 0x0 >;      /* in zephyr/dts/riscv/espressif/esp32h2/esp32h2_common.dtsi:304 */
			interrupt-parent = < &intc >;       /* in zephyr/dts/riscv/espressif/esp32h2/esp32h2_common.dtsi:305 */
			clocks = < &clock 0x6 >;            /* in zephyr/dts/riscv/espressif/esp32h2/esp32h2_common.dtsi:306 */
			dmas = < &dma 0x2 >,
			       < &dma 0x3 >;                /* in zephyr/dts/riscv/espressif/esp32h2/esp32h2_common.dtsi:307 */
			dma-names = "rx",
			            "tx";                   /* in zephyr/dts/riscv/espressif/esp32h2/esp32h2_common.dtsi:308 */
			unit = < 0x0 >;                     /* in zephyr/dts/riscv/espressif/esp32h2/esp32h2_common.dtsi:309 */
			status = "disabled";                /* in zephyr/dts/riscv/espressif/esp32h2/esp32h2_common.dtsi:310 */
			pinctrl-0 = < &i2s_default >;       /* in zephyr/boards/espressif/esp32h2_devkitm/esp32h2_devkitm.dts:87 */
			pinctrl-names = "default";          /* in zephyr/boards/espressif/esp32h2_devkitm/esp32h2_devkitm.dts:88 */
		};

		/* node '/soc/adc@6000e000' defined in zephyr/dts/riscv/espressif/esp32h2/esp32h2_common.dtsi:313 */
		adc0: adc@6000e000 {
			compatible = "espressif,esp32-adc"; /* in zephyr/dts/riscv/espressif/esp32h2/esp32h2_common.dtsi:314 */
			reg = < 0x6000e000 0x4 >;           /* in zephyr/dts/riscv/espressif/esp32h2/esp32h2_common.dtsi:315 */
			clocks = < &clock 0x1c >;           /* in zephyr/dts/riscv/espressif/esp32h2/esp32h2_common.dtsi:316 */
			unit = < 0x1 >;                     /* in zephyr/dts/riscv/espressif/esp32h2/esp32h2_common.dtsi:317 */
			channel-count = < 0x5 >;            /* in zephyr/dts/riscv/espressif/esp32h2/esp32h2_common.dtsi:318 */
			#io-channel-cells = < 0x1 >;        /* in zephyr/dts/riscv/espressif/esp32h2/esp32h2_common.dtsi:319 */
			status = "disabled";                /* in zephyr/dts/riscv/espressif/esp32h2/esp32h2_common.dtsi:320 */
		};

		/* node '/soc/ledc@60008000' defined in zephyr/dts/riscv/espressif/esp32h2/esp32h2_common.dtsi:323 */
		ledc0: ledc@60008000 {
			compatible = "espressif,esp32-ledc"; /* in zephyr/dts/riscv/espressif/esp32h2/esp32h2_common.dtsi:324 */
			pwm-controller;                      /* in zephyr/dts/riscv/espressif/esp32h2/esp32h2_common.dtsi:325 */
			#pwm-cells = < 0x3 >;                /* in zephyr/dts/riscv/espressif/esp32h2/esp32h2_common.dtsi:326 */
			reg = < 0x60008000 0x1000 >;         /* in zephyr/dts/riscv/espressif/esp32h2/esp32h2_common.dtsi:327 */
			clocks = < &clock 0x0 >;             /* in zephyr/dts/riscv/espressif/esp32h2/esp32h2_common.dtsi:328 */
			status = "disabled";                 /* in zephyr/dts/riscv/espressif/esp32h2/esp32h2_common.dtsi:329 */
		};

		/* node '/soc/mcpwm@60014000' defined in zephyr/dts/riscv/espressif/esp32h2/esp32h2_common.dtsi:332 */
		mcpwm0: mcpwm@60014000 {
			compatible = "espressif,esp32-mcpwm"; /* in zephyr/dts/riscv/espressif/esp32h2/esp32h2_common.dtsi:333 */
			reg = < 0x60014000 0x1000 >;          /* in zephyr/dts/riscv/espressif/esp32h2/esp32h2_common.dtsi:334 */
			interrupts = < 0x31 0x0 0x0 >;        /* in zephyr/dts/riscv/espressif/esp32h2/esp32h2_common.dtsi:335 */
			interrupt-parent = < &intc >;         /* in zephyr/dts/riscv/espressif/esp32h2/esp32h2_common.dtsi:336 */
			clocks = < &clock 0x18 >;             /* in zephyr/dts/riscv/espressif/esp32h2/esp32h2_common.dtsi:337 */
			#pwm-cells = < 0x3 >;                 /* in zephyr/dts/riscv/espressif/esp32h2/esp32h2_common.dtsi:338 */
			status = "disabled";                  /* in zephyr/dts/riscv/espressif/esp32h2/esp32h2_common.dtsi:339 */
		};

		/* node '/soc/can@6000c000' defined in zephyr/dts/riscv/espressif/esp32h2/esp32h2_common.dtsi:342 */
		twai: can@6000c000 {
			compatible = "espressif,esp32-twai"; /* in zephyr/dts/riscv/espressif/esp32h2/esp32h2_common.dtsi:343 */
			reg = < 0x6000c000 0x1000 >;         /* in zephyr/dts/riscv/espressif/esp32h2/esp32h2_common.dtsi:344 */
			interrupts = < 0x24 0x0 0x0 >;       /* in zephyr/dts/riscv/espressif/esp32h2/esp32h2_common.dtsi:345 */
			interrupt-parent = < &intc >;        /* in zephyr/dts/riscv/espressif/esp32h2/esp32h2_common.dtsi:346 */
			clocks = < &clock 0xe >;             /* in zephyr/dts/riscv/espressif/esp32h2/esp32h2_common.dtsi:347 */
			status = "disabled";                 /* in zephyr/dts/riscv/espressif/esp32h2/esp32h2_common.dtsi:348 */
			pinctrl-0 = < &twai_default >;       /* in zephyr/boards/espressif/esp32h2_devkitm/esp32h2_devkitm.dts:92 */
			pinctrl-names = "default";           /* in zephyr/boards/espressif/esp32h2_devkitm/esp32h2_devkitm.dts:93 */
		};

		/* node '/soc/pcnt@60012000' defined in zephyr/dts/riscv/espressif/esp32h2/esp32h2_common.dtsi:351 */
		pcnt: pcnt@60012000 {
			compatible = "espressif,esp32-pcnt"; /* in zephyr/dts/riscv/espressif/esp32h2/esp32h2_common.dtsi:352 */
			reg = < 0x60012000 0x1000 >;         /* in zephyr/dts/riscv/espressif/esp32h2/esp32h2_common.dtsi:353 */
			interrupts = < 0x32 0x0 0x0 >;       /* in zephyr/dts/riscv/espressif/esp32h2/esp32h2_common.dtsi:354 */
			interrupt-parent = < &intc >;        /* in zephyr/dts/riscv/espressif/esp32h2/esp32h2_common.dtsi:355 */
			clocks = < &clock 0xb >;             /* in zephyr/dts/riscv/espressif/esp32h2/esp32h2_common.dtsi:356 */
			status = "disabled";                 /* in zephyr/dts/riscv/espressif/esp32h2/esp32h2_common.dtsi:357 */
		};

		/* node '/soc/sha@6003b000' defined in zephyr/dts/riscv/espressif/esp32h2/esp32h2_common.dtsi:360 */
		sha: sha@6003b000 {
			compatible = "espressif,esp32-sha"; /* in zephyr/dts/riscv/espressif/esp32h2/esp32h2_common.dtsi:361 */
			reg = < 0x6003b000 0x100 >;         /* in zephyr/dts/riscv/espressif/esp32h2/esp32h2_common.dtsi:362 */
			clocks = < &clock 0x12 >;           /* in zephyr/dts/riscv/espressif/esp32h2/esp32h2_common.dtsi:363 */
			status = "okay";                    /* in zephyr/dts/riscv/espressif/esp32h2/esp32h2_common.dtsi:364 */
		};

		/* node '/soc/aes@6003a000' defined in zephyr/dts/riscv/espressif/esp32h2/esp32h2_common.dtsi:367 */
		aes: aes@6003a000 {
			compatible = "espressif,esp32-aes"; /* in zephyr/dts/riscv/espressif/esp32h2/esp32h2_common.dtsi:368 */
			reg = < 0x6003a000 0x1000 >;        /* in zephyr/dts/riscv/espressif/esp32h2/esp32h2_common.dtsi:369 */
			clocks = < &clock 0x11 >;           /* in zephyr/dts/riscv/espressif/esp32h2/esp32h2_common.dtsi:370 */
			status = "okay";                    /* in zephyr/dts/riscv/espressif/esp32h2/esp32h2_common.dtsi:371 */
		};
	};

	/* node '/gpio_keys' defined in zephyr/boards/espressif/esp32h2_devkitm/esp32h2_devkitm.dts:32 */
	gpio_keys {
		compatible = "gpio-keys"; /* in zephyr/boards/espressif/esp32h2_devkitm/esp32h2_devkitm.dts:33 */

		/* node '/gpio_keys/button_1' defined in zephyr/boards/espressif/esp32h2_devkitm/esp32h2_devkitm.dts:35 */
		user_button1: button_1 {
			label = "User SW1";          /* in zephyr/boards/espressif/esp32h2_devkitm/esp32h2_devkitm.dts:36 */
			gpios = < &gpio0 0x9 0x11 >; /* in zephyr/boards/espressif/esp32h2_devkitm/esp32h2_devkitm.dts:37 */
			zephyr,code = < 0xb >;       /* in zephyr/boards/espressif/esp32h2_devkitm/esp32h2_devkitm.dts:38 */
		};
	};
};
